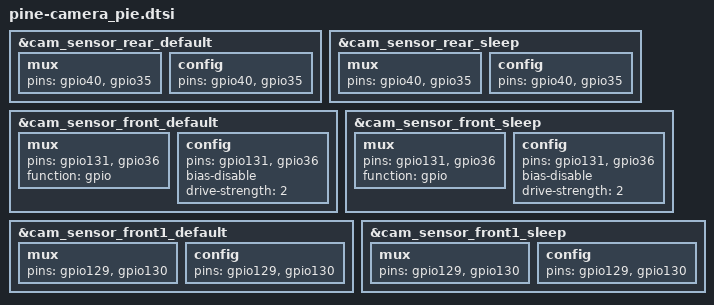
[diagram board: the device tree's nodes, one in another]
&cam_sensor_rear_default {
	mux {
		pins = "gpio40", "gpio35";
	};

	config {
		pins = "gpio40", "gpio35";
	};
};

&cam_sensor_rear_sleep {
	mux {
		pins = "gpio40", "gpio35";
	};

	config {
		pins = "gpio40", "gpio35";
	};
};

&cam_sensor_front_default {
	mux {
		pins = "gpio131", "gpio36";
		function = "gpio";
	};

	config {
		pins = "gpio131", "gpio36";
		bias-disable; /* No PULL */
		drive-strength = <2>; /* 2 MA */
	};
};

&cam_sensor_front_sleep {
	mux {
		pins = "gpio131", "gpio36";
		function = "gpio";
	};

	config {
		pins = "gpio131", "gpio36";
		bias-disable; /* No PULL */
		drive-strength = <2>; /* 2 MA */
	};
};

&cam_sensor_front1_default {
	mux {
		pins = "gpio129", "gpio130";
	};

	config {
		pins = "gpio129", "gpio130";
	};
};

&cam_sensor_front1_sleep {
	mux {
		pins = "gpio129", "gpio130";
	};

	config {
		pins = "gpio129", "gpio130";
	};
};
